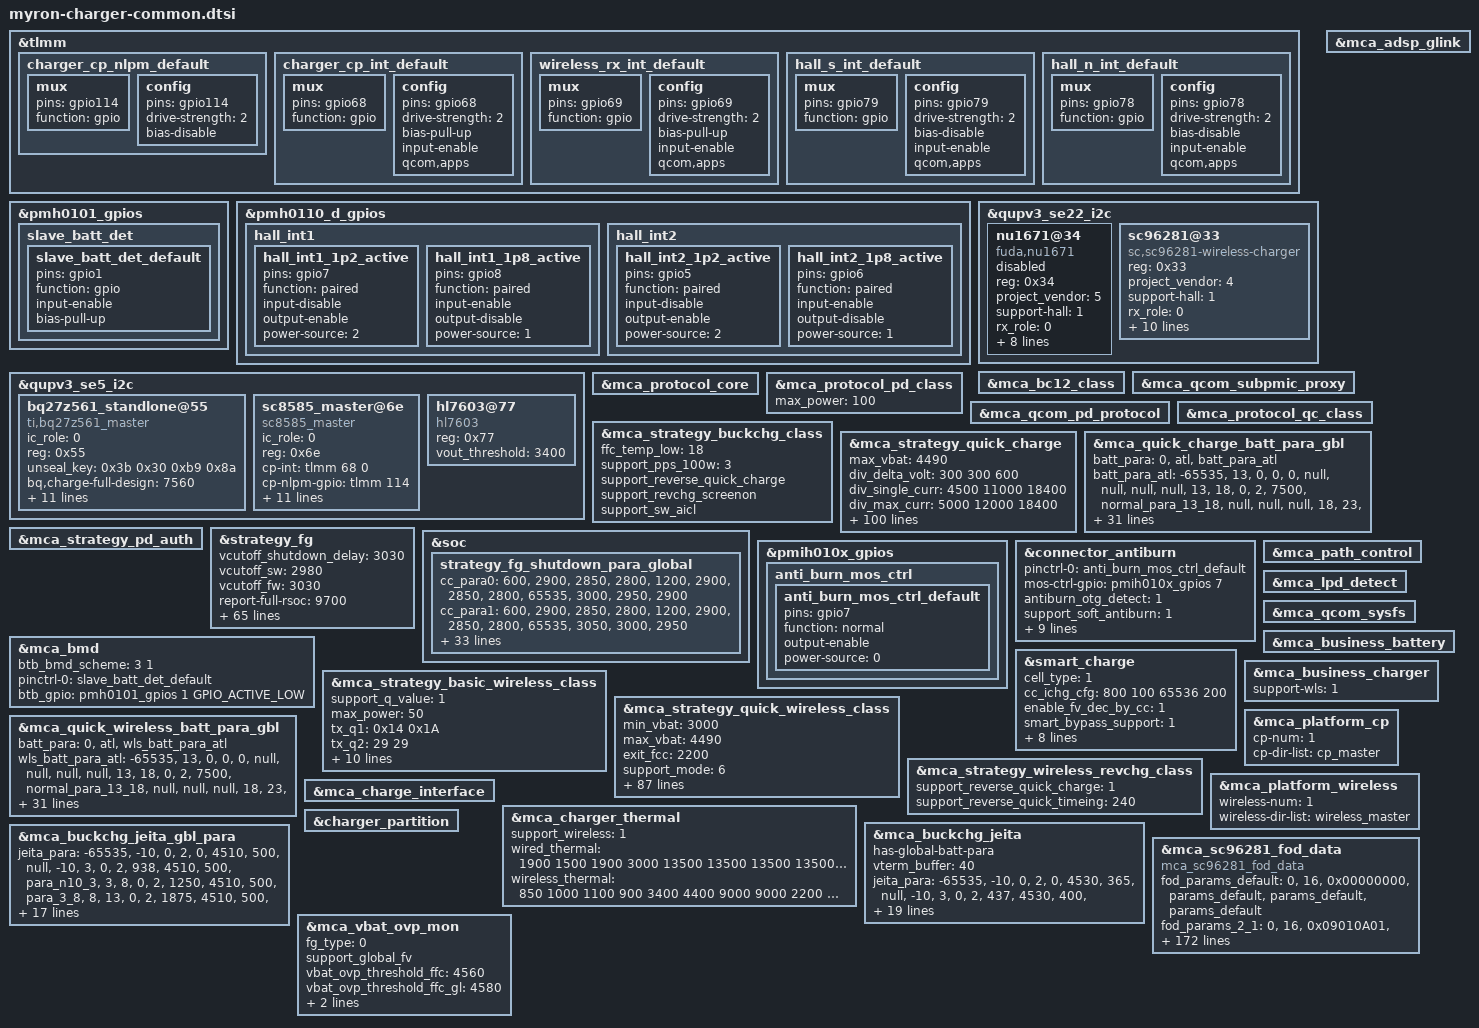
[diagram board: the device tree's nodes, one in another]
#include "mca.dtsi"

&tlmm {
	charger_cp_nlpm_default: charger_cp_nlpm_default {
		mux {
			pins = "gpio114";
			function = "gpio";
		};
		config {
			pins = "gpio114";
			drive-strength = <2>;   /* 2 mA */
			bias-disable;
		};
	};

	charger_cp_int_default: charger_cp_int_default {
		mux {
			pins = "gpio68";
			function = "gpio";
		};
		config {
			pins = "gpio68";
			drive-strength = <2>;   /* 2 mA */
			bias-pull-up;
			input-enable;
			qcom,apps;
		};
	};

	wireless_rx_int_default: wireless_rx_int_default {
		mux {
			pins = "gpio69";
			function = "gpio";
		};

		config {
			pins = "gpio69";
			drive-strength = <2>;
			bias-pull-up;
			input-enable;
			qcom,apps;
		};
	};

	hall_s_int_default: hall_s_int_default {
		mux {
			pins = "gpio79";
			function = "gpio";
		};

		config {
			pins = "gpio79";
			drive-strength = <2>;
			bias-disable;
			input-enable;
			qcom,apps;
		};
	};

	hall_n_int_default: hall_n_int_default {
		mux {
			pins = "gpio78";
			function = "gpio";
		};

		config {
			pins = "gpio78";
			drive-strength = <2>;
			bias-disable;
			input-enable;
			qcom,apps;
		};
	};
};

&pmh0101_gpios {
	slave_batt_det {
		slave_batt_det_default: slave_batt_det_default {
			pins = "gpio1";
			function = "gpio";
			input-enable;
			bias-pull-up;
		};
	};
};

&pmh0110_d_gpios {
	hall_int1 {
		hall_int1_1p2_active: hall_int1_1p2_active {
			pins = "gpio7";
			function = "paired";
			input-disable;
			output-enable;
			power-source = <2>;
		};

		hall_int1_1p8_active: hall_int1_1p8_active {
			pins = "gpio8";
			function = "paired";
			input-enable;
			output-disable;
			power-source = <1>;
		};
	};

	hall_int2 {
		hall_int2_1p2_active: hall_int2_1p2_active {
			pins = "gpio5";
			function = "paired";
			input-disable;
			output-enable;
			power-source = <2>;
		};

		hall_int2_1p8_active: hall_int2_1p8_active {
			pins = "gpio6";
			function = "paired";
			input-enable;
			output-disable;
			power-source = <1>;
		};
	};
};

&qupv3_se5_i2c {
	status = "ok";
	#address-cells = <1>;
	#size-cells = <0>;
	bq27z561_standlone@55 {
		compatible = "ti,bq27z561_master";
		ic_role = <0>;
		reg = <0x55>;
		unseal_key = /bits/ 8 <0x3b 0x30 0xb9 0x8a>;
		bq,charge-full-design = <7560>;
		soh_th = <92>;
		cycle_th = <400>;
		cycle_step = <50>;
		resistance-id = <100000>;
		support_batt_manager_4p0;
		base_termv = <3030>;
		base_termv_gl = <3200>;
		delta_soh_compesation = <
			0 0
			50 2
			100 5
			150 7
			200 9
			250 12
			300 15
			350 18
			400 18
			450 18
			500 18>;
		delta_soh_compesation_gl = <
			0 0
			50 1
			100 2
			150 4
			200 5
			250 5
			300 5
			350 5
			400 5
			450 5
			500 5>;
		status = "ok";
	};

	sc8585_master@6e {
		compatible = "sc8585_master";
		status = "ok";
		ic_role = <0>;
		reg = <0x6e>;
		cp-int = <&tlmm 68 0>;
		cp-nlpm-gpio = <&tlmm 114 0x00>;
		pinctrl-names = "default";
		pinctrl-0 = <&charger_cp_nlpm_default>, <&charger_cp_int_default>;
		bat-ovp-threshold = <4700>;
		bat-ovp-alarm-threshold = <4650>;
		bus-ovp-threshold = <21000 12000 6000>;
		usb-ovp-threshold = <21000 14000 7500>;
		bus-ocp-threshold = <5000 5500 5000>;
		wpc-ovp-threshold = <21000>;
		out-ovp-threshold = <5000>;
		pmid2-uvp-threshold = <350 350 100>;
		pmid2-ovp-threshold = <600>;
	};

	hl7603@77 {
		compatible = "hl7603";
		reg = <0x77>;
		vout_threshold = <3400>;
	};
};

&qupv3_se22_i2c {
	status = "ok";
	#address-cells = <1>;
	#size-cells = <0>;

	nu1671@34 {
		compatible = "fuda,nu1671";
		reg = <0x34>;
		project_vendor = <5>;
		support-hall = <1>;
		rx_role = <0>;
		fw_version_index = <0>;
		pinctrl-names = "default";
		pinctrl-0 = <&wireless_rx_int_default>, <&hall_s_int_default>, <&hall_n_int_default>;
		rx-int = <&tlmm 69 0x00>;
		pwr-det-int = <&tlmm 57 0x00>;
		sleep-rx-gpio = <&tlmm 200 0x00>;
		hall-s-int = <&tlmm 79 0x00>;
		hall-n-int = <&tlmm 78 0x00>;
		status = "disabled";
	};

	sc96281@33 {
		compatible = "sc,sc96281-wireless-charger";
		reg = <0x33>;
		project_vendor = <4>;
		support-hall = <1>;
		rx_role = <0>;
		fw_version_index = <1>;
		pinctrl-names = "default";
		pinctrl-0 = <&wireless_rx_int_default>, <&hall_s_int_default>, <&hall_n_int_default>, <&hall_int1_1p2_active>, <&hall_int1_1p8_active>, <&hall_int2_1p2_active>, <&hall_int2_1p8_active>;
		rx-int = <&tlmm 69 0x00>;
		pwr-det-int = <&tlmm 57 0x00>;
		sleep-rx-gpio = <&tlmm 200 0x00>;
		hall-s-int = <&tlmm 79 0x00>;
		hall-n-int = <&tlmm 78 0x00>;
	};
};

&mca_adsp_glink {
	status = "ok";
};

&mca_bc12_class {
	status = "ok";
};

&mca_qcom_subpmic_proxy {
	status = "ok";
};

&mca_protocol_core {
	status = "ok";
};

&mca_protocol_pd_class {
	status = "ok";
	max_power = <100>;
};

&mca_qcom_pd_protocol {
	status = "ok";
};

&mca_protocol_qc_class {
	status = "ok";
};

&mca_strategy_buckchg_class {
	status = "ok";
	ffc_temp_low = <18>;
	support_pps_100w = <3>;
	support_reverse_quick_charge;
	support_revchg_screenon;
	support_sw_aicl;
};

&mca_strategy_quick_charge {
	status = "ok";
	max_vbat = <4490>;
	div_delta_volt = <300 300 600>;
	div_single_curr = <4500 11000 18400>;
	div_max_curr = <5000 12000 18400>;
	non_mi_pps_max_curr = <4500 11000 18400>;
	real_curr_max = <17500>;
	curr_monitor_current = <17600>;
	curr_monitor_time_s = <120>;
	support_mode = <6>;
	support_cp_vfc = <1>;
	support_cancel_compensation;
	has-global-batt-para;
	en_buck_parallel_chg = <1>;
	max_vbat_threshold = <4580>;
	buck_icl_fcc_curr = <1000 3000>;
	buck_en_th = <13000 2500>;
	buck_dis_th = <13000 3850>;
	qc_normal_charge_fv = <4480>;

	vstep_para =
		"1", "300", "2000", "0", "2",
		"2", "300", "2000", "0", "4",
		"4", "300", "8000", "0", "25",
		"4", "300", "4000", "20", "17",
		"4", "300", "2000", "10", "8",
		"4", "300", "1200", "10", "5",
		"4", "300", "800", "0", "2",
		"1", "800", "2000", "0", "2",
		"2", "800", "2000", "0", "4",
		"4", "800", "8000", "0", "10",
		"4", "800", "6000", "0", "5",
		"4", "800", "4000", "0", "2";

	batt_para =
		"0", "atl", "batt_para_atl",
		"0", "coslight", "batt_para_cos";

	/* temp_low, temp_high, low_hys, high_hys, max_curr, normal_para, ffc_para, normal_stage, ffc_stage */
	batt_para_atl =
		"-65535", "13", "0", "0", "0", "null", "null", "null", "null",
		"13", "18", "0", "2", "4374", "normal_para_atl_13_18", "null", "null", "null",
		"18", "23", "0", "1", "12400", "normal_para_atl_18_23", "ffc_para_atl_18_23", "null", "ffc_stage_atl_18_23",
		"23", "35", "0", "0", "18400", "normal_para_atl_23_35", "ffc_para_atl_23_35", "null", "ffc_stage_atl_23_35",
		"35", "40", "1", "0", "18400", "normal_para_atl_35_40", "ffc_para_atl_35_40", "null", "ffc_stage_atl_35_40",
		"40", "48", "1", "0", "18400", "normal_para_atl_40_48", "ffc_para_atl_40_48", "null", "ffc_stage_atl_40_48",
		"48", "65535", "2", "0", "0", "null", "null", "null", "null";

	batt_para_cos =
		"-65535", "13", "0", "0", "0", "null", "null", "null", "null",
		"13", "18", "0", "2", "4386", "normal_para_cos_13_18", "null", "null", "null",
		"18", "23", "0", "1", "12400", "normal_para_cos_18_23", "ffc_para_cos_18_23", "null", "ffc_stage_cos_18_23",
		"23", "35", "0", "0", "18400", "normal_para_cos_23_35", "ffc_para_cos_23_35", "null", "ffc_stage_cos_23_35",
		"35", "40", "1", "0", "18400", "normal_para_cos_35_40", "ffc_para_cos_35_40", "null", "ffc_stage_cos_35_40",
		"40", "48", "1", "0", "18400", "normal_para_cos_40_48", "ffc_para_cos_40_48", "null", "ffc_stage_cos_40_48",
		"48", "65535", "2", "0", "0", "null", "null", "null", "null";

	normal_para_atl_13_18 = "4200", "4374", "2916", "4525", "2916", "365";
	normal_para_atl_18_23 = "4250", "12400", "8748", "4505", "8748", "365";
	normal_para_atl_23_35 = "4190", "18400", "8748", "4505", "8748", "365";
	normal_para_atl_35_40 = "4190", "18400", "8748", "4495", "8748", "365";
	normal_para_atl_40_48 = "4190", "18400", "8748", "4485", "8748", "365";

	ffc_para_atl_18_23 = "4250", "12400", "10935", "4500", "10935", "8748", "4555", "8748", "1094";
	ffc_para_atl_23_35 = "4190", "18400", "12400", "4290", "12400", "10935", "4500", "10935", "8748", "4555", "8748", "1458";
	ffc_para_atl_35_40 = "4190", "18400", "12400", "4290", "12400", "10935", "4500", "10935", "8748", "4555", "8748", "2333";
	ffc_para_atl_40_48 = "4190", "18400", "12400", "4290", "12400", "10935", "4500", "10935", "8748", "4555", "8748", "3208";

	ffc_stage_atl_18_23 = <0 0 0 0 0 0>;
	ffc_stage_atl_23_35 = <0 1 0 0 0 0 0 0>;
	ffc_stage_atl_35_40 = <0 1 0 0 0 0 0 0>;
	ffc_stage_atl_40_48 = <0 1 0 0 0 0 0 0>;

	normal_para_cos_13_18 = "4200", "4386", "2924", "4525", "2924", "366";
	normal_para_cos_18_23 = "4250", "12400", "8772", "4505", "8772", "366";
	normal_para_cos_23_35 = "4290", "18400", "8772", "4505", "8772", "366";
	normal_para_cos_35_40 = "4290", "18400", "8772", "4495", "8772", "366";
	normal_para_cos_40_48 = "4290", "18400", "8772", "4485", "8772", "366";

	ffc_para_cos_18_23 = "4250", "12400", "10965", "4500", "10965", "8772", "4555", "8772", "810";
	ffc_para_cos_23_35 = "4290", "18400", "12400", "4350", "12400", "10965", "4500", "10965", "8772", "4555", "8772", "1023";
	ffc_para_cos_35_40 = "4290", "18400", "12400", "4350", "12400", "10965", "4500", "10965", "8772", "4555", "8772", "1608";
	ffc_para_cos_40_48 = "4290", "18400", "12400", "4350", "12400", "10965", "4500", "10965", "8772", "4555", "8772", "2339";

	ffc_stage_cos_18_23 = <0 0 0 0 0 0>;
	ffc_stage_cos_23_35 = <0 1 0 0 0 0 0 0>;
	ffc_stage_cos_35_40 = <0 1 0 0 0 0 0 0>;
	ffc_stage_cos_40_48 = <0 1 0 0 0 0 0 0>;
};

&mca_quick_charge_batt_para_gbl {
	batt_para = "0", "atl", "batt_para_atl";

	batt_para_atl =
		"-65535", "13", "0", "0", "0", "null", "null", "null", "null",
		"13", "18", "0", "2", "7500", "normal_para_13_18", "null", "null", "null",
		"18", "23", "0", "1", "12500", "normal_para_18_23", "null", "null", "null",
		"23", "35", "0", "0", "18000", "normal_para_23_35", "ffc_para_23_35", "null", "ffc_stage_23_35",
		"35", "40", "1", "0", "18000", "normal_para_35_40", "ffc_para_35_40", "null", "ffc_stage_35_40",
		"40", "48", "1", "0", "18000", "normal_para_40_48", "ffc_para_40_48", "null", "ffc_stage_40_48",
		"48", "65535", "2", "0", "0", "null", "null", "null", "null";

	normal_para_13_18 = "4200", "7500", "6250", "4505", "6250", "500";
	normal_para_18_23 = "4200", "12500", "9375", "4505", "9375", "500";
	normal_para_23_35 = "4150", "18000", "7500", "4505", "7500", "500";
	normal_para_35_40 = "4150", "18000", "7500", "4475", "7500", "500";
	normal_para_40_48 = "4150", "18000", "7500", "4465", "7500", "500";

	ffc_para_23_35 = "4150", "18000", "12400", "4350", "12400", "11250", "4400", "11250", "9375", "4500", "9375", "7500", "4555", "7500", "2500";
	ffc_para_35_40 = "4150", "18000", "12400", "4350", "12400", "11250", "4400", "11250", "9375", "4500", "9375", "7500", "4555", "7500", "3562";
	ffc_para_40_48 = "4150", "18000", "12400", "4350", "12400", "11250", "4400", "11250", "9375", "4500", "9375", "7500", "4555", "7500", "5000";

	ffc_stage_23_35 = <0 0 0 0 0 0 0 0 0 0>;
	ffc_stage_35_40 = <0 0 0 0 0 0 0 0 0 0>;
	ffc_stage_40_48 = <0 0 0 0 0 0 0 0 0 0>;
};

&mca_strategy_pd_auth {
	status = "ok";
};

&strategy_fg {
	status = "ok";
	vcutoff_shutdown_delay = <3030>;
	vcutoff_sw = <2980>;
	vcutoff_fw = <3030>;
	report-full-rsoc = <9700>;
	soc-proportion = <98>;
	soc-proportion-c = <97>;
	support-pnc;
	support-vpack-low-shutdown;

	support-cc-vcutoff;
	/* temp_low, temp_high, low_temp_hys, high_temp_hys, vterm_para_name */
	cc_vcutoff_cfg =
		"-65535", "-6", "0", "2", "cc_para0",
		"-6", "0", "2", "2", "cc_para1",
		"0", "10", "2", "2", "cc_para2",
		"10", "60", "2", "0", "cc_para3",
		"60", "65535", "2", "0", "cc_para4";
	/* cycle_count, vterm_fw, vterm_shutdown_delay, vempty */
	cc_para0 =
		"400", "2650", "2600", "2500",
		"800", "2700", "2650", "2600",
		"1200", "2850", "2800", "2750",
		"65535", "2950", "2900", "2850";
	cc_para1 =
		"400", "2700", "2650", "2600",
		"800", "2850", "2800", "2750",
		"1200", "2950", "2900", "2850",
		"65535", "3050", "3000", "2950";
	cc_para2 =
		"400", "2850", "2850", "2800",
		"800", "2950", "2950", "2900",
		"1200", "3000", "3000", "2950",
		"65535", "3100", "3100", "3050";
	cc_para3 =
		"400", "3030", "3030", "2980",
		"800", "3130", "3130", "3080",
		"1200", "3200", "3200", "3150",
		"65535", "3260", "3260", "3210";
	cc_para4 =
		"65535", "3260", "3260", "3210";

	support-dod-vcutoff-v2;
	weight = <20 18 15>;
	/* temp_low, temp_high, low_temp_hys, high_temp_hys, vterm_para_name */
	dod_vcutoff_cfg =
		"-65535", "-6", "0", "2", "dod_para0",
		"-6", "0", "2", "2", "dod_para1",
		"0", "10", "2", "2", "dod_para2",
		"10", "60", "2", "0", "dod_para3",
		"60", "65535", "2", "0", "dod_para4";
	/* dod_count, vterm_fw, vterm_shutdown_delay, vempty */
	dod_para0 =
		"79", "2650", "2600", "2500",
		"159", "2700", "2650", "2600",
		"413", "2850", "2800", "2750",
		"1050", "2950", "2900", "2850",
		"65535", "3050", "3000", "2950";
	dod_para1 =
		"79", "2700", "2650", "2600",
		"159", "2850", "2800", "2750",
		"413", "2950", "2900", "2850",
		"1050", "3050", "3000", "2950",
		"65535", "3150", "3100", "3050";
	dod_para2 =
		"79", "2850", "2850", "2800",
		"159", "2950", "2950", "2900",
		"413", "3000", "3000", "2950",
		"1050", "3100", "3100", "3050",
		"65535", "3200", "3200", "3150";
	dod_para3 =
		"79", "3030", "3030", "2980",
		"159", "3130", "3130", "3080",
		"413", "3200", "3200", "3150",
		"1050", "3260", "3260", "3210",
		"65535", "3310", "3310", "3260";
	dod_para4 =
		"65535", "3310", "3310", "3260";
	adapt_power = <100>;
	model-name = "P11U_7560mah_100w";
	model-name-global = "P11U_6500mah_100w";
	charge-full-design = <7560>;
	charge-full-design-gl = <6500>;
	support_full_design_gl;
	support_dynamic_capacity_comp;
	capacity_comp = <0>;
	capacity_comp_gl = <0>;
	has_global_shutdown_para;
	support_dtpt = <1>;
	fg_hightemp_vterm = <4200>;
	support-lossless-rechg = <1>;
	lossless_rechg_cfg = <18 47 90>;
	support_normal_force_full;
	normal_force_full_hys = <116>;
	suppot_RSOC_0_smooth = <1>;
	smooth_temp_unit = <0 150>; //15℃
	smooth_curr_unit = <0 300000 600000 1000000>;
	smooth_vol_offset = <0x80000000 0 100 200 300>;
	dischg_smooth_low_temp_unit = <
		10 10 10 10
		20 10 10 10
		40 20 10 10
		80 40 30 20
		150 80 70 50 >;
	dischg_smooth_high_temp_unit = <
		10 10 10 10
		30 20 10 10
		60 40 20 10
		150 70 50 40
		200 150 100 70 >;
};

&soc {
	strategy_fg_shutdown_para_global: strategy_fg_shutdown_para_global {
		cc_para0 = "600", "2900", "2850", "2800", "1200", "2900", "2850", "2800", "65535", "3000", "2950", "2900";
		cc_para1 = "600", "2900", "2850", "2800", "1200", "2900", "2850", "2800", "65535", "3050", "3000", "2950";
		cc_para2 = "600", "2950", "2950", "2900", "1200", "3050", "3050", "3000", "65535", "3150", "3150", "3100";
		cc_para3 = "12", "3050", "3050", "3000", "600", "3200", "3200", "3150", "1200", "3280", "3280", "3230", "65535", "3350", "3350", "3300";
		cc_para4 = "65535", "3350", "3350", "3300";
		cc_vcutoff_cfg = "-65535", "-6", "0", "2", "cc_para0", "-6", "0", "2", "2", "cc_para1", "0", "10", "2", "2", "cc_para2", "10", "60", "2", "0", "cc_para3", "60", "65535", "2", "0", "cc_para4";
		dod_para0 = "94", "2900", "2850", "2800", "281", "2900", "2850", "2800", "563", "3000", "2950", "2900", "65535", "3050", "3000", "2950";
		dod_para1 = "94", "2900", "2850", "2800", "281", "2900", "2850", "2800", "563", "3050", "3000", "2950", "65535", "3200", "3150", "3100";
		dod_para2 = "94", "2950", "2950", "2900", "281", "3050", "3050", "3000", "563", "3150", "3150", "3100", "65535", "3300", "3300", "3250";
		dod_para3 = "30", "3050", "3050", "3000", "94", "3200", "3200", "3150", "281", "3280", "3280", "3230", "563", "3350", "3350", "3300", "65535", "3400", "3400", "3380";
		dod_para4 = "65535", "3400", "3400", "3380";
		dod_vcutoff_cfg = "-65535", "-6", "0", "2", "dod_para0", "-6", "0", "2", "2", "dod_para1", "0", "10", "2", "2", "dod_para2", "10", "60", "2", "0", "dod_para3", "60", "65535", "2", "0", "dod_para4";
		support-cc-vcutoff;
		support-dod-vcutoff;
		vcutoff_fw = <3050>;
		vcutoff_shutdown_delay = <3050>;
		vcutoff_sw = <3000>;
		weight = <30 21 14>;
	};
};

&pmih010x_gpios {
	anti_burn_mos_ctrl {
		anti_burn_mos_ctrl_default: anti_burn_mos_ctrl_default {
			pins = "gpio7";
			function = "normal";
			output-enable;
			//drive-strength = <2>;
			power-source = <0>;
		};
	};
};

&connector_antiburn {
	status = "ok";
	pinctrl-names = "default";
	pinctrl-0 = <&anti_burn_mos_ctrl_default>;
	mos-ctrl-gpio = <&pmih010x_gpios 7 0>;
	antiburn_otg_detect = <1>;
	support_soft_antiburn = <1>;
	support_hw_antiburn = <1>;
	use_double_ntc = <1>;
	monitor_interval = <1000>;
	thermal-zone-name = "conn_therm";
	thermal-zone-name2 = "conn_therm2";
	max_temp_increase_rate = <4>; /*ntc temperature increase speed per second.*/
	otg_boost_src = <2>; /* HBOOST */
	en_src = <0>; /* OTG_EN_BOOST */
	thermal-board-temp-name = "board_sensor_therm";
};

&mca_bmd {
	status = "ok";
	btb_bmd_scheme = <3 1>;
	pinctrl-names = "default";
	pinctrl-0 = <&slave_batt_det_default>;
	btb_gpio = <&pmh0101_gpios 1 GPIO_ACTIVE_LOW>;
};

&smart_charge {
	status = "ok";
	cell_type = <1>;
	// support_cc_ichg;
	/* cyclecount delta_ichg*/
	cc_ichg_cfg = <
		800 100
		65536 200>;
	enable_fv_dec_by_cc = <1>;
	smart_bypass_support = <1>;
	smart_bypass_entry_soc = <40>;
	support_csd = <0>;

	/* temp_low, temp_high, low_temp_hys, high_temp_hys, fcc */
	smart_bypass_high_lmt_cfg = <
		(-100) 150 5 5 4500
		151 200 5 5 4500
		201	250	5 5 4500
		251	300	5 5 3500
		301	370	5 5 2500
		371	800	5 5 1000>;
	smart_bypass_med_lmt_cfg = <
		(-100) 150 5 5 18400
		151	200	5 5 18400
		201	250	5 5 18400
		251	300	5 5 8000
		301	370	5 5 5000
		371	800	5 5 2000>;
	smart_bypass_low_lmt_cfg = <
		(-100) 150 5 5 18400
		151	200	5 5 18400
		201	250	5 5 18400
		251	300	5 5 9000
		301	370	5 5 5000
		371	800	5 5 3000>;
};

&mca_path_control {
	status = "ok";
};

&mca_lpd_detect {
	status = "ok";
};

&mca_strategy_basic_wireless_class {
	status = "ok";
	support_q_value = <1>;
	max_power = <50>;
	tx_q1 = /bits/ 8 <0x14 0x1A>;
	tx_q2 = <29 29>;
	rx_max_iout = <2650 2650>;
	wls_vdd_src = <2>;
	ffc_temp_low = <15>;
	ffc_temp_high = <48>;
	support-hall = <1>;
	support-dynamic-cp = <1>;
	dynamic-cp-uuid = <0x09010a01>;
	dynamic-cp-min-tx-adapter = <14>;	
	dynamic-cp-4to2-threshold = <6000>;
	dynamic-cp-2-1-max-fcc = <9200>;
};

&mca_strategy_quick_wireless_class {
	status = "ok";
	min_vbat = <3000>;
	max_vbat = <4490>;
	exit_fcc = <2200>;
	support_mode = <6>;
	div_single_curr = <0 9200 9200>;
	div_max_curr = <0 9200 9200>;
	support-hall = <1>;
	has-global-batt-para;
	batt_para =
		"0", "atl", "wls_batt_para_atl",
		"0", "coslight", "wls_batt_para_cos";

	/* temp_low, temp_high, low_hys, high_hys, max_curr, normal_para, ffc_para, normal_stage, ffc_stage */
	wls_batt_para_atl =
		"-65535", "13", "0", "0", "0", "null", "null", "null", "null",
		"13", "18", "0", "2", "4374", "normal_para_atl_13_18", "null", "null", "null",
		"18", "23", "0", "1", "12400", "normal_para_atl_18_23", "ffc_para_atl_18_23", "null", "ffc_stage_atl_18_23",
		"23", "35", "0", "0", "17600", "normal_para_atl_23_35", "ffc_para_atl_23_35", "null", "ffc_stage_atl_23_35",
		"35", "40", "1", "0", "17600", "normal_para_atl_35_40", "ffc_para_atl_35_40", "null", "ffc_stage_atl_35_40",
		"40", "48", "1", "0", "17600", "normal_para_atl_40_48", "ffc_para_atl_40_48", "null", "ffc_stage_atl_40_48",
		"48", "65535", "2", "0", "0", "null", "null", "null", "null";

	normal_para_atl_13_18 =
		"4200", "4374", "2916",
		"4520", "2916", "800";

	normal_para_atl_18_23 =
		"4250", "12400", "8748",
		"4500", "8748", "800";

	normal_para_atl_23_35 =
		"4190", "17600", "8748",
		"4500", "8748", "800";

	normal_para_atl_35_40 =
		"4190", "17600", "8748",
		"4490", "8748", "800";

	normal_para_atl_40_48 =
		"4190", "17600", "8748",
		"4480", "8748", "800";

	ffc_para_atl_18_23 =
		"4250", "12400", "10935",
		"4500", "10935", "8748",
		"4550", "8748", "2300";

	ffc_para_atl_23_35 =
		"4190", "17600", "12400",
		"4290", "12400", "10935",
		"4500", "10935", "8748",
		"4550", "8748", "2300";

	ffc_para_atl_35_40 =
		"4190", "17600", "12400",
		"4290", "12400", "10935",
		"4500", "10935", "8748",
		"4550", "8748", "3000";

	ffc_para_atl_40_48 =
		"4190", "17600", "12400",
		"4290", "12400", "10935",
		"4500", "10935", "8748",
		"4540", "8748", "4000";

	ffc_stage_atl_18_23 = <0 1 0 0 0 0>;
	ffc_stage_atl_23_35 = <0 1 0 0 0 0 0 0>;
	ffc_stage_atl_35_40 = <0 1 0 0 0 0 0 0>;
	ffc_stage_atl_40_48 = <0 1 0 0 0 0 0 0>;

	wls_batt_para_cos =
		"-65535", "13", "0", "0", "0", "null", "null", "null", "null",
		"13", "18", "0", "2", "4386", "normal_para_cos_13_18", "null", "null", "null",
		"18", "23", "0", "1", "12400", "normal_para_cos_18_23", "ffc_para_cos_18_23", "null", "ffc_stage_cos_18_23",
		"23", "35", "0", "0", "17600", "normal_para_cos_23_35", "ffc_para_cos_23_35", "null", "ffc_stage_cos_23_35",
		"35", "40", "1", "0", "17600", "normal_para_cos_35_40", "ffc_para_cos_35_40", "null", "ffc_stage_cos_35_40",
		"40", "48", "1", "0", "17600", "normal_para_cos_40_48", "ffc_para_cos_40_48", "null", "ffc_stage_cos_40_48",
		"48", "65535", "2", "0", "0", "null", "null", "null", "null";

	normal_para_cos_13_18 =
		"4200", "4386", "2924",
		"4520", "2924", "800";

	normal_para_cos_18_23 =
		"4250", "12400", "8772",
		"4500", "8772", "800";

	normal_para_cos_23_35 =
		"4290", "17600", "8772",
		"4500", "8772", "800";

	normal_para_cos_35_40 =
		"4290", "17600", "8772",
		"4490", "8772", "800";

	normal_para_cos_40_48 =
		"4290", "17600", "8772",
		"4480", "8772", "800";

	ffc_para_cos_18_23 =
		"4250", "12400", "10965",
		"4500", "10965", "8772",
		"4550", "8772", "2300";

	ffc_para_cos_23_35 =
		"4290", "17600", "12400",
		"4350", "12400", "10965",
		"4500", "10965", "8772",
		"4550", "8772", "2300";

	ffc_para_cos_35_40 =
		"4290", "17600", "12400",
		"4350", "12400", "10965",
		"4500", "10965", "8772",
		"4550", "8772", "2300";

	ffc_para_cos_40_48 =
		"4290", "17600", "12400",
		"4350", "12400", "10965",
		"4500", "10965", "8772",
		"4540", "8772", "3000";

	ffc_stage_cos_18_23 = <0 1 0 0 0 0>;
	ffc_stage_cos_23_35 = <0 1 0 0 0 0 0 0>;
	ffc_stage_cos_35_40 = <0 1 0 0 0 0 0 0>;
	ffc_stage_cos_40_48 = <0 1 0 0 0 0 0 0>;

	vstep_para =
		"1", "2000", "2",
		"2", "4000", "25",
		"2", "3000", "25",
		"2", "2000", "4",
		"4", "4000", "25",
		"4", "3000", "25",
		"4", "2000", "6",
		"4", "1000", "3",
		"4", "500", "2",
		"4", "200", "1";
};

&mca_quick_wireless_batt_para_gbl {
	batt_para = "0", "atl", "wls_batt_para_atl";

	wls_batt_para_atl =
		"-65535", "13", "0", "0", "0", "null", "null", "null", "null",
		"13", "18", "0", "2", "7500", "normal_para_13_18", "null", "null", "null",
		"18", "23", "0", "1", "12500", "normal_para_18_23", "null", "null", "null",
		"23", "35", "0", "0", "17600", "normal_para_23_35", "ffc_para_23_35", "null", "ffc_stage_23_35",
		"35", "40", "1", "0", "17600", "normal_para_35_40", "ffc_para_35_40", "null", "ffc_stage_35_40",
		"40", "48", "1", "0", "17600", "normal_para_40_48", "ffc_para_40_48", "null", "ffc_stage_40_48",
		"48", "65535", "0", "0", "0", "null", "null", "null", "null";

	normal_para_13_18 = "4200", "7500", "6250", "4500", "6250", "800";
	normal_para_18_23 = "4200", "12500", "9375", "4500", "9375", "800";
	normal_para_23_35 = "4150", "17600", "7500", "4480", "7500", "800";
	normal_para_35_40 = "4150", "17600", "7500", "4470", "7500", "800";
	normal_para_40_48 = "4150", "17600", "7500", "4460", "7500", "800";

	ffc_para_23_35 = "4150", "17600", "12400", "4350", "12400", "11250", "4400", "11250", "9375", "4500", "9375", "7500", "4550", "7500", "4000";
	ffc_para_35_40 = "4150", "17600", "12400", "4350", "12400", "11250", "4400", "11250", "9375", "4500", "9375", "7500", "4510", "7500", "4000";
	ffc_para_40_48 = "4150", "17600", "12400", "4350", "12400", "11250", "4400", "11250", "9375", "4500", "9375", "7500", "4510", "7500", "4000";

	ffc_stage_23_35 = <0 1 0 0 0 0 0 0 0 0>;
	ffc_stage_35_40 = <0 1 0 0 0 0 0 0 0 0>;
	ffc_stage_40_48 = <0 1 0 0 0 0 0 0 0 0>;
};

&mca_strategy_wireless_revchg_class {
	status = "ok";
	support_reverse_quick_charge = <1>;
	support_reverse_quick_timeing = <240>;  //sec
};

&mca_qcom_sysfs {
	status = "ok";
};

&mca_business_battery {
	status = "ok";
};

&mca_business_charger {
	support-wls = <1>;
	status = "ok";
};

&mca_platform_cp {
	status = "ok";
	cp-num = <1>;
	cp-dir-list = "cp_master";
};

&mca_platform_wireless {
	status = "ok";
	wireless-num = <1>;
	wireless-dir-list = "wireless_master";
};

&mca_charge_interface {
	status = "ok";
};

&mca_charger_thermal {
	status = "ok";
	support_wireless = <1>;
	/* 5v_in 9v_in 5v_ichg 9v_ichg div1_single div1_multi div2_single div2_multi div4_single div4_multi*/
	wired_thermal = <
		1900 1500 1900 3000 13500 13500 13500 13500 13500 13500 /* level 1 */
		1900 1500 1900 3000 11000 11000 11000 11000 11000 11000 /* level 2 */
		1900 1500 1900 3000 9000  9000  9000  9000  9000  9000  /* level 3 */
		1900 1450 1900 3000 8000  8000  8000  8000  8000  8000  /* level 4 */
		1900 1400 1900 3000 7000  7000  7000  7000  7000  7000  /* level 5 */
		1900 1350 1900 2800 6000  6000  6000  6000  6000  6000  /* level 6 */
		1900 1300 1900 2600 5000  5000  5000  5000  5000  5000  /* level 7 */
		1900 1150 1900 2310 4000  4000  4000  4000  4000  4000  /* level 8 */
		1700 1100 1700 2200 3500  3500  3500  3500  3500  3500  /* level 9 */
		1600 1000 1600 2000 3000  3000  3000  3000  3000  3000  /* level 10 */
		1400 900  1500 2000 2500  2500  2500  2500  2500  2500  /* level 11 */
		1200 850  1500 2000 2000  2000  2000  2000  2000  2000  /* level 12 */
		1100 750  1500 1500 1500  1500  1500  1500  1500  1500  /* level 13 */
		1100 650  1000 1000 1000  1000  1000  1000  1000  1000  /* level 14 */
		1100 600  500  500  500   500   500   500   500   500   /* level 15 */
	>;
	/* bpp_in bpp_qc2 bpp_qc3 epp_in cp_20w cp_30w cp_50w cp_80w voice_box magnet_30w*/
	wireless_thermal = <
		850 1000 1100 900 3400 4400 9000 9000 2200 4400 /* level 1 */
		850 1000 1100 750 3200 4200 8000 8000 2200 4200 /* level 2 */
		850 1000 1100 650 2200 3400 7000 7000 1000 3400 /* level 3 */
		700 1000 1100 650 1800 2800 6000 6000 1000 2800 /* level 4 */
		700 1000  700 650 1500 2600 5000 5000  800 2600 /* level 5 */
		500 1000  700 650 1300 2200 4000 4000  800 2200 /* level 6 */
		500  700  600 400 1100 2200 3500 3500  700 2200 /* level 7 */
		500  700  600 400 1000 1800 3000 3000  700 1800 /* level 8 */
		500  500  500 300  800 1100 2500 2500  600 1100 /* level 9 */
		400  500  500 300  700 1000 2000 2000  600 1000 /* level 10 */
		400  500  500 250  600  800 1500 1500  500  800 /* level 11 */
		400  500  500 250  500  700 1000 1000  500  700 /* level 12 */
		300  500  500 250  500  600  800  800  400  600 /* level 13 */
		300  400  400 200  400  500  500  500  400  500 /* level 14 */
		300  300  300 150  300  400  400  400  300  400 /* level 15 */
	>;
};

&mca_buckchg_jeita {
	status = "ok";
	has-global-batt-para;
	vterm_buffer = <40>;
	/* temp_low, temp_high, low_temp_hys, high_temp_hys, max_current, vterm, iterm volt_para_name */
	jeita_para =
		"-65535", "-10", "0", "2", "0", "4530", "365", "null",
		"-10", "3", "0", "2", "437", "4530", "400", "para_n10_3",
		"3", "8", "0", "2", "1094", "4530", "365", "para_3_8",
		"8", "13", "0", "2", "2187", "4530", "365", "para_8_13",
		"13", "18", "0", "2", "4000", "4530", "365", "para_13_18",
		"18", "23", "0", "1", "4000", "4510", "365", "null",
		"23", "35", "0", "0", "4000", "4510", "365", "null",
		"35", "40", "1", "0", "4000", "4500", "365", "null",
		"40", "48", "1", "0", "4000", "4490", "365", "null",
		"48", "55", "2", "0", "3645", "4080", "365", "null",
		"55", "65535", "2", "2", "0", "4080", "365", "null";
	para_n10_3 =
		"4530", "437";
	para_3_8 =
		"4200", "1094",
		"4530", "729";
	para_8_13 =
		"4200", "2187",
		"4530", "1458";
	para_13_18 =
		"4200", "4374",
		"4530", "2916";
	jeita_para_ffc =
		"18", "23", "0", "1", "4000", "4560", "1114", "null",
		"23", "35", "0", "0", "4000", "4560", "1458", "null",
		"35", "40", "1", "0", "4000", "4560", "2333", "null",
		"40", "48", "1", "0", "4000", "4560", "3208", "null",
		"48", "55", "2", "0", "3645", "4080", "365", "null",
		"55", "65535", "2", "2", "0", "4080", "365", "null";
};

&mca_buckchg_jeita_gbl_para {
	jeita_para =
		"-65535", "-10", "0", "2", "0", "4510", "500", "null",
		"-10", "3", "0", "2", "938", "4510", "500", "para_n10_3",
		"3", "8", "0", "2", "1250", "4510", "500", "para_3_8",
		"8", "13", "0", "2", "1875", "4510", "500", "para_8_13",
		"13", "18", "0", "2", "4000", "4510", "500", "para_13_18",
		"18", "23", "0", "1", "4000", "4510", "500", "para_18_23",
		"23", "35", "0", "0", "4000", "4490", "500", "null",
		"35", "40", "1", "0", "4000", "4480", "500", "null",
		"40", "48", "1", "0", "4000", "4470", "500", "null",
		"48", "55", "2", "0", "3125", "4080", "500", "null",
		"55", "65535", "2", "2", "0", "4080", "500", "null";
	jeita_para_ffc =
		"23", "35", "0", "0", "4000", "4560", "2812", "null",
		"35", "40", "1", "0", "4000", "4560", "4062", "null",
		"40", "48", "1", "0", "4000", "4560", "6062", "null",
		"48", "55", "2", "0", "3125", "4080", "500", "null",
		"55", "65535", "2", "2", "0", "4080", "500", "null";
	para_13_18 = "4200", "4000", "4510", "4000";
	para_18_23 = "4200", "4000", "4510", "4000";
	para_3_8 = "4200", "1250", "4510", "938";
	para_8_13 = "4200", "1875", "4510", "1250";
	para_n10_3 = "4200", "938", "4510", "625";
};

/* use big endian number instead to avoid massive unreadable code */
&mca_sc96281_fod_data {
	compatible = "mca_sc96281_fod_data";
	
	fod_params_default = "0", "16", "0x00000000", "params_default", "params_default", "params_default";
	fod_params_2_1 = "0", "16", "0x09010A01", "params_2_1_m2_50W", "params_2_1_m2_50W_mag", "params_2_1_m2_50W_mag";

	fod_params = 
		"0", "16", "0x0901090C", "params_k8_100W", "params_k8_100W_mag", "params_k8_100W_mag", 
		"0", "16", "0x09010305", "params_low_inductance_80w", "params_low_inductance_80w_mag", "params_low_inductance_80w_mag", 
		"0", "16", "0x09010901", "params_l2_50W", "params_l2_50W_mag", "params_l2_50W_mag", 
		"0", "16", "0x09010407", "params_white_stand_30W", "params_white_stand_30W_mag", "params_white_stand_30W_mag", 
		"0", "16", "0x09010904", "params_k1_80W", "params_k1_80W_mag", "params_k1_80W_mag", 
		"0", "16", "0x09010A01", "params_m2_50W", "params_m2_50W_mag", "params_m2_50W_mag", 
		"0", "16", "0x0901010B", "params_j1s_55W", "params_j1s_55W_mag", "params_j1s_55W_mag", 
		"0", "16", "0x01080205", "params_zimi_car_50W", "params_zimi_car_50W_mag", "params_zimi_car_50W_mag", 
		"0", "16", "0x09080207", "params_zimi_car_30W", "params_zimi_car_30W_mag", "params_zimi_car_30W_mag", 
		"0", "16", "0x09010907", "params_redmi_disc_30W", "params_redmi_disc_30W_mag", "params_redmi_disc_30W_mag", 
		"0", "16", "0x09080108", "params_zimi_20W", "params_zimi_20W_mag", "params_zimi_20W_mag", 
		"0", "16", "0x09010506", "params_moving_20W", "params_moving_20W_mag", "params_moving_20W_mag", 
		"0", "16", "0x09010A07", "params_double_coil_30W", "params_double_coil_30W_mag", "params_double_coil_30W_mag", 
		"0", "16", "0x06010101", "params_white_20W", "params_white_20W_mag", "params_white_20W_mag", 
		"0", "16", "0x0C090908", "params_multcoil_20W", "params_multcoil_20W_mag", "params_multcoil_20W_mag", 
		"0", "16", "0x06020801", "params_zimi_car_20W", "params_zimi_car_20W_mag", "params_zimi_car_20W_mag", 
		"0", "16", "0x09080607", "params_bluetooth_30W", "params_bluetooth_30W_mag", "params_bluetooth_30W_mag", 
		"0", "16", "0x07030801", "params_power_bank_30W", "params_power_bank_30W_mag", "params_power_bank_30W_mag", 
		"0", "16", "0x02010203", "params_trx_rev_22P5W", "params_trx_rev_22P5W_mag", "params_trx_rev_22P5W_mag", 
		"0", "16", "0x09018B07", "params_magnet_30W", "params_magnet_30W_mag", "params_magnet_30W_mag", 
		"0", "16", "0x09058907", "params_magnet_2in1_30W", "params_magnet_2in1_30W_mag", "params_magnet_2in1_30W_mag", 
		"0", "16", "0x07030802", "params_black_vertical_30W_mag", "params_black_vertical_30W_mag", "params_black_vertical_30W_mag", 
		"0", "16", "0x0E018207", "params_magnet_black_car_30W_mag", "params_magnet_black_car_30W_mag", "params_magnet_black_car_30W_mag", 
		"0", "16", "0x02010B03", "params_p11u_trx_rev_22P5W_mag", "params_p11u_trx_rev_22P5W_mag", "params_p11u_trx_rev_22P5W_mag", 
		"0", "16", "0x09018203", "params_black_fan_mag", "params_black_fan_mag", "params_black_fan_mag", 
		"0", "16", "0x09018207", "params_black_short_mike_mag", "params_black_short_mike_mag", "params_black_short_mike_mag";

	params_default = <0x9b2d9b1e 0x961e951e 0x941e8728 0x87288728 0x87288728 0x87288728 0x87288728 0x87288728>;
	params_2_1_m2_50W = <0x8e328e32 0x8e328e32 0x8e328519 0x85148414 0x83147c1e 0x7c1e7e19 0x7e197f19 0x8014801e>;
	params_2_1_m2_50W_mag = <0xa0469b32 0x96329632 0x8c288923 0x861e821e 0x811e811e 0x80287f28 0x7f287f2d 0x7f2d7f2d>;

	params_k8_100W = <0x9b379b28 0x9628951e 0x94238c2d 0x9614960f 0x8a328c28 0x8c288d2d 0x8d2d8d2d 0x8d288d28>;
	params_k8_100W_mag = <0x9b3c9b28 0x961e9519 0x94198c19 0x96059602 0x8a1e8c14 0x8c148d0f 0x8d058d05 0x8d058d05>;
	params_k1_80W = <0x9b379b37 0x962d952d 0x90288c23 0x8c238c23 0x8c238c28 0x8d2d8d2d 0x8d2d8d2d 0x8d348d34>;
	params_k1_80W_mag = <0x9b289b23 0x961e9519 0x94198c1e 0x960a960a 0x8a1e8c14 0x8c148d14 0x8d0f8d0f 0x8d058d05>;
	params_low_inductance_80w = <0x7d287d28 0x7d287d28 0x7f288323 0x7d287e2d 0x7a287a28 0x7a287928 0x7828782d 0x78327832>;
	params_low_inductance_80w_mag = <0x6e146f1e 0x711e731e 0x74286e1e 0x6e146f19 0x6f197019 0x70197019 0x701e701e 0x7128712d>;

	params_l2_50W = <0x9652961e 0x96149514 0x94148c1e 0x93009600 0x8a1e8c0f 0x8c0f8d0f 0x8d058c00 0x8b008b00>;
	params_l2_50W_mag = <0x4637554f 0x6846654b 0x67506e46 0x6e436c50 0x67596f50 0x71436e5a 0x782d7827 0x78277c14>;
	params_m2_50W = <0x8e328e32 0x8e328e32 0x8e32a056 0x8c468a34 0x8c3e8c3e 0x8c3e9020 0x8e328e32 0x8e148c1e>;
	params_m2_50W_mag = <0x993c9537 0x9532943c 0x99329941 0x99469832 0x90288e28 0x8d288b2d 0x8a378a37 0x8a3c8a3c>;
	params_j1s_55W = <0x9652961e 0x96149514 0x94148c1e 0x93009600 0x8a1e8c0f 0x8c0f8d0f 0x8d058c00 0x8b008b00>;
	params_j1s_55W_mag = <0x9b3c9b37 0x96329523 0x94238c1e 0x960a960a 0x8a1e8c14 0x8c148d14 0x8c008c00 0x8b008b00>;

	params_zimi_car_50W = <0x9b2d9b1e 0x961e951e 0x941e8728 0x87288728 0x87288728 0x87288728 0x87288728 0x87288728>;
	params_zimi_car_50W_mag = <0x9b2d9b1e 0x961e951e 0x941e8c1e 0x960a9600 0x8a1e8c14 0x8c148d14 0x8d0f8d05 0x8d058d05>;
	params_zimi_car_30W = <0x80287f22 0x7f227f22 0x7e227d26 0x7d267c29 0x7c2b7b28 0x7e247e24 0x80288028 0x80288028>;
	params_zimi_car_30W_mag = <0x80287f22 0x7f227f22 0x7e227d26 0x7d267c29 0x7c2b7b28 0x7e247e24 0x80288028 0x80288028>;
	params_zimi_car_20W = <0x9b2d9b1e 0x961e951e 0x941e8728 0x87288728 0x87288728 0x87288728 0x87288728 0x87288728>;
	params_zimi_car_20W_mag = <0x9b2d9b1e 0x961e951e 0x941e8728 0x87288728 0x87288728 0x87288728 0x87288728 0x87288728>;
	params_zimi_20W = <0x9b379b2d 0x962d9528 0x94288732 0x87328732 0x87328732 0x87328732 0x87328732 0x87328732>;
	params_zimi_20W_mag = <0x781e7c2d 0x7f287f28 0x7f287f28 0x80287f28 0x80288028 0x80288028 0x80288028 0x80288028>;
	params_magnet_black_car_30W_mag = <0x9b2d9b1e 0x961e951e 0x941e8c1e 0x960a9600 0x8a1e8c14 0x8c148d14 0x8d0f8d05 0x8d058d05>;

	params_white_stand_30W = <0x9652963c 0x96289528 0x94288c0f 0x96149619 0x8a328c2d 0x8c2d8d2d 0x8d238e00 0x8e008e00>;
	params_white_stand_30W_mag = <0x9b4b9b4b 0x96469537 0x94288c28 0x960a960a 0x8a1e8c14 0x8c148d14 0x8d0f8d0f 0x8d058d0f>;
	params_redmi_disc_30W = <0x9652963c 0x96289528 0x94198c0a 0x96149614 0x8a288c23 0x8c238d23 0x8d198e00 0x8e008e00>;
	params_redmi_disc_30W_mag = <0x9b3c9b2d 0x9614950f 0x94198c14 0x96009600 0x8a198c14 0x8c0a8d0a 0x8d058d00 0x8d008d00>;
	params_black_vertical_30W_mag = <0x9b2d9b1e 0x961e951e 0x941e8c1e 0x960a9600 0x8a1e8c14 0x8c148d14 0x8d0f8d05 0x8d058d05>;

	params_moving_20W = <0x9b2d9b1e 0x961e951e 0x941e8728 0x87288728 0x87288728 0x87288728 0x87288728 0x87288728>;
	params_moving_20W_mag = <0x7a1e7920 0x7b167e15 0x7e1b7e1b 0x7a187a18 0x7a187a18 0x7a187a18 0x7a187a18 0x7a187a18>;
	params_double_coil_30W = <0x96349614 0x960a9500 0x940a8c0a 0x96149f28 0x8a008c05 0x8f008d0a 0x8d008e00 0x8e008e00>;
	params_double_coil_30W_mag = <0x9b289b19 0x9614950f 0x94198c1e 0x960a9600 0x8a1e8c14 0x8c148d14 0x8d0f8d05 0x8d058d05>;
	params_multcoil_20W = <0x9b419b3c 0x963c953c 0x943c8741 0x87418741 0x87418741 0x87418741 0x87418741 0x87418741>;
	params_multcoil_20W_mag = <0x7819780a 0x780f7814 0x66136f19 0x7b197b1e 0x810f7c14 0x7e147e14 0x70287028 0x70287028>;

	params_power_bank_30W = <0x9b2d9b1e 0x961e951e 0x941e8c1e 0x960a9600 0x8a1e8c14 0x8c148d14 0x8d0f8d05 0x8d058d05>;
	params_power_bank_30W_mag = <0x9b2d9b1e 0x961e951e 0x941e8c1e 0x960a9600 0x8a1e8c14 0x8c148d14 0x8d0f8d05 0x8d058d05>;
	params_bluetooth_30W = <0x9b2d9b1e 0x961e951e 0x941e8728 0x87288728 0x87288728 0x87288728 0x87288728 0x87288728>;
	params_bluetooth_30W_mag = <0x9b2d9b1e 0x961e951e 0x941e8728 0x87288728 0x87288728 0x87288728 0x87288728 0x87288728>;
	
	params_magnet_30W = <0x7a027a02 0x7b027c02 0x82028302 0x83028402 0x84028402 0x84028402 0x84028402 0x84028402>;
	params_magnet_30W_mag = <0x7a027a02 0x7b027c02 0x82028302 0x83028402 0x84028402 0x84028402 0x84028402 0x84028402>;
	params_magnet_2in1_30W = <0x8c328c32 0x8f329132 0x8d328a28 0x8a28892d 0x892d892d 0x89328932 0x89328a37 0x8a378a37>;
	params_magnet_2in1_30W_mag = <0x8c328c32 0x8f329132 0x8d328a28 0x8a28892d 0x892d892d 0x89328932 0x89328a37 0x8a378a37>;

	params_trx_rev_22P5W = <0x8e288e24 0x8e1e8e1a 0x8a148a10 0x88108810 0x88108810 0x88108810 0x88108810 0x88108810>;
	params_trx_rev_22P5W_mag = <0x8e288e24 0x8e1e8e1a 0x8a148a10 0x88108810 0x88108810 0x88108810 0x88108810 0x88108810>;
	params_p11u_trx_rev_22P5W_mag = <0x9b3c9b2d 0x96329523 0x942d8c28 0x96289628 0x8a288c28 0x8c288d28 0x8d288d28 0x8d288d28>;

	params_white_20W = <0x9b2d9b1e 0x961e951e 0x941e8c1e 0x960a9600 0x8a1e8c14 0x8c148d14 0x8d0f8d05 0x8d058d05>;
	params_white_20W_mag = <0x9b2d9b1e 0x961e951e 0x941e8c1e 0x960a9600 0x8a1e8c14 0x8c148d14 0x8d0f8d05 0x8d058d05>;
	params_black_fan_mag = <0x6e146f1e 0x711e731e 0x74286e1e 0x6e146f19 0x6f197019 0x70197019 0x701e701e 0x7128712d>;
	params_black_short_mike_mag = <0x6e146f1e 0x711e731e 0x74286e1e 0x6e146f19 0x6f197019 0x70197019 0x701e701e 0x7128712d>;
};

&charger_partition {
	status = "ok";
};

&mca_vbat_ovp_mon {
	status = "ok";
	fg_type = <0>;
	support_global_fv;
	vbat_ovp_threshold_ffc = <4560>;
	vbat_ovp_threshold_ffc_gl = <4580>;
	vbat_ovp_threshold_normal = <4510>;
	vbat_ovp_threshold_normal_gl = <4530>;
};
